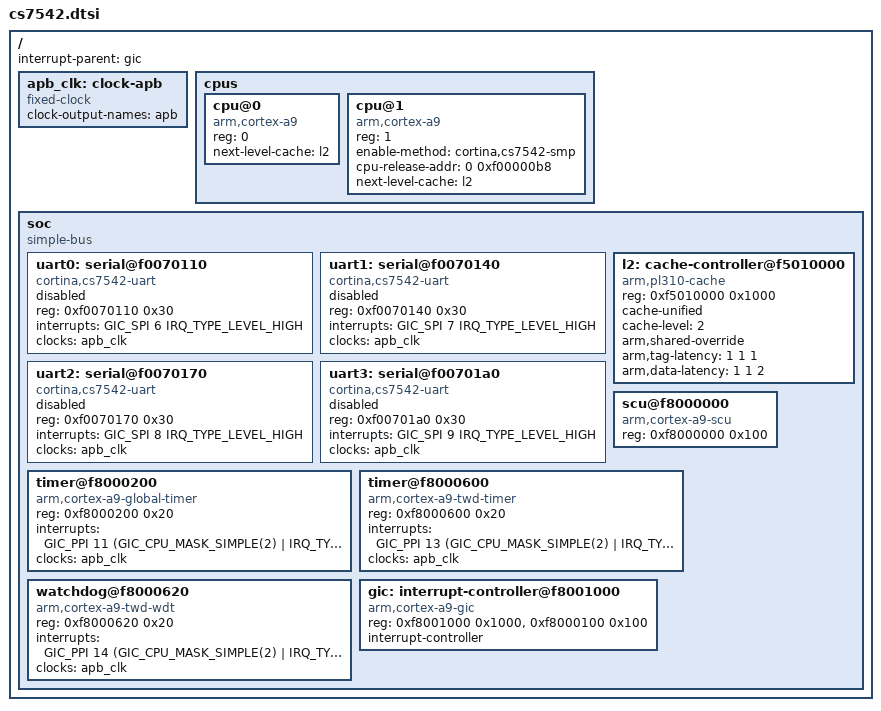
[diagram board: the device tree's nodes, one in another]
// SPDX-License-Identifier: (GPL-2.0-or-later OR MIT)
/*
 * Device Tree Source for the Cortina Systems CS7542 SoC
 */

#include <dt-bindings/interrupt-controller/arm-gic.h>

/ {
	#address-cells = <1>;
	#size-cells = <1>;
	interrupt-parent = <&gic>;

	/* Rate is selected by the boot strap pins, set by the board */
	apb_clk: clock-apb {
		compatible = "fixed-clock";
		#clock-cells = <0>;
		clock-output-names = "apb";
	};

	cpus {
		#address-cells = <1>;
		#size-cells = <0>;

		cpu@0 {
			device_type = "cpu";
			compatible = "arm,cortex-a9";
			reg = <0>;
			next-level-cache = <&l2>;
		};

		cpu@1 {
			device_type = "cpu";
			compatible = "arm,cortex-a9";
			reg = <1>;
			enable-method = "cortina,cs7542-smp";
			cpu-release-addr = <0 0xf00000b8>;
			next-level-cache = <&l2>;
		};
	};

	soc {
		compatible = "simple-bus";
		ranges;
		#address-cells = <1>;
		#size-cells = <1>;

		uart0: serial@f0070110 {
			compatible = "cortina,cs7542-uart";
			reg = <0xf0070110 0x30>;
			interrupts = <GIC_SPI 6 IRQ_TYPE_LEVEL_HIGH>;
			clocks = <&apb_clk>;

			status = "disabled";
		};

		uart1: serial@f0070140 {
			compatible = "cortina,cs7542-uart";
			reg = <0xf0070140 0x30>;
			interrupts = <GIC_SPI 7 IRQ_TYPE_LEVEL_HIGH>;
			clocks = <&apb_clk>;

			status = "disabled";
		};

		uart2: serial@f0070170 {
			compatible = "cortina,cs7542-uart";
			reg = <0xf0070170 0x30>;
			interrupts = <GIC_SPI 8 IRQ_TYPE_LEVEL_HIGH>;
			clocks = <&apb_clk>;

			status = "disabled";
		};

		uart3: serial@f00701a0 {
			compatible = "cortina,cs7542-uart";
			reg = <0xf00701a0 0x30>;
			interrupts = <GIC_SPI 9 IRQ_TYPE_LEVEL_HIGH>;
			clocks = <&apb_clk>;

			status = "disabled";
		};

		l2: cache-controller@f5010000 {
			compatible = "arm,pl310-cache";
			reg = <0xf5010000 0x1000>;
			cache-unified;
			cache-level = <2>;
			arm,shared-override;
			arm,tag-latency = <1 1 1>;
			arm,data-latency = <1 1 2>;
		};

		scu@f8000000 {
			compatible = "arm,cortex-a9-scu";
			reg = <0xf8000000 0x100>;
		};

		timer@f8000200 {
			compatible = "arm,cortex-a9-global-timer";
			reg = <0xf8000200 0x20>;
			interrupts = <GIC_PPI 11 (GIC_CPU_MASK_SIMPLE(2) | IRQ_TYPE_EDGE_RISING)>;
			clocks = <&apb_clk>;
		};

		timer@f8000600 {
			compatible = "arm,cortex-a9-twd-timer";
			reg = <0xf8000600 0x20>;
			interrupts = <GIC_PPI 13 (GIC_CPU_MASK_SIMPLE(2) | IRQ_TYPE_EDGE_RISING)>;
			clocks = <&apb_clk>;
		};

		watchdog@f8000620 {
			compatible = "arm,cortex-a9-twd-wdt";
			reg = <0xf8000620 0x20>;
			interrupts = <GIC_PPI 14 (GIC_CPU_MASK_SIMPLE(2) | IRQ_TYPE_EDGE_RISING)>;
			clocks = <&apb_clk>;
		};

		gic: interrupt-controller@f8001000 {
			compatible = "arm,cortex-a9-gic";
			reg = <0xf8001000 0x1000>,
			      <0xf8000100 0x100>;
			#interrupt-cells = <3>;
			interrupt-controller;
		};
	};
};
